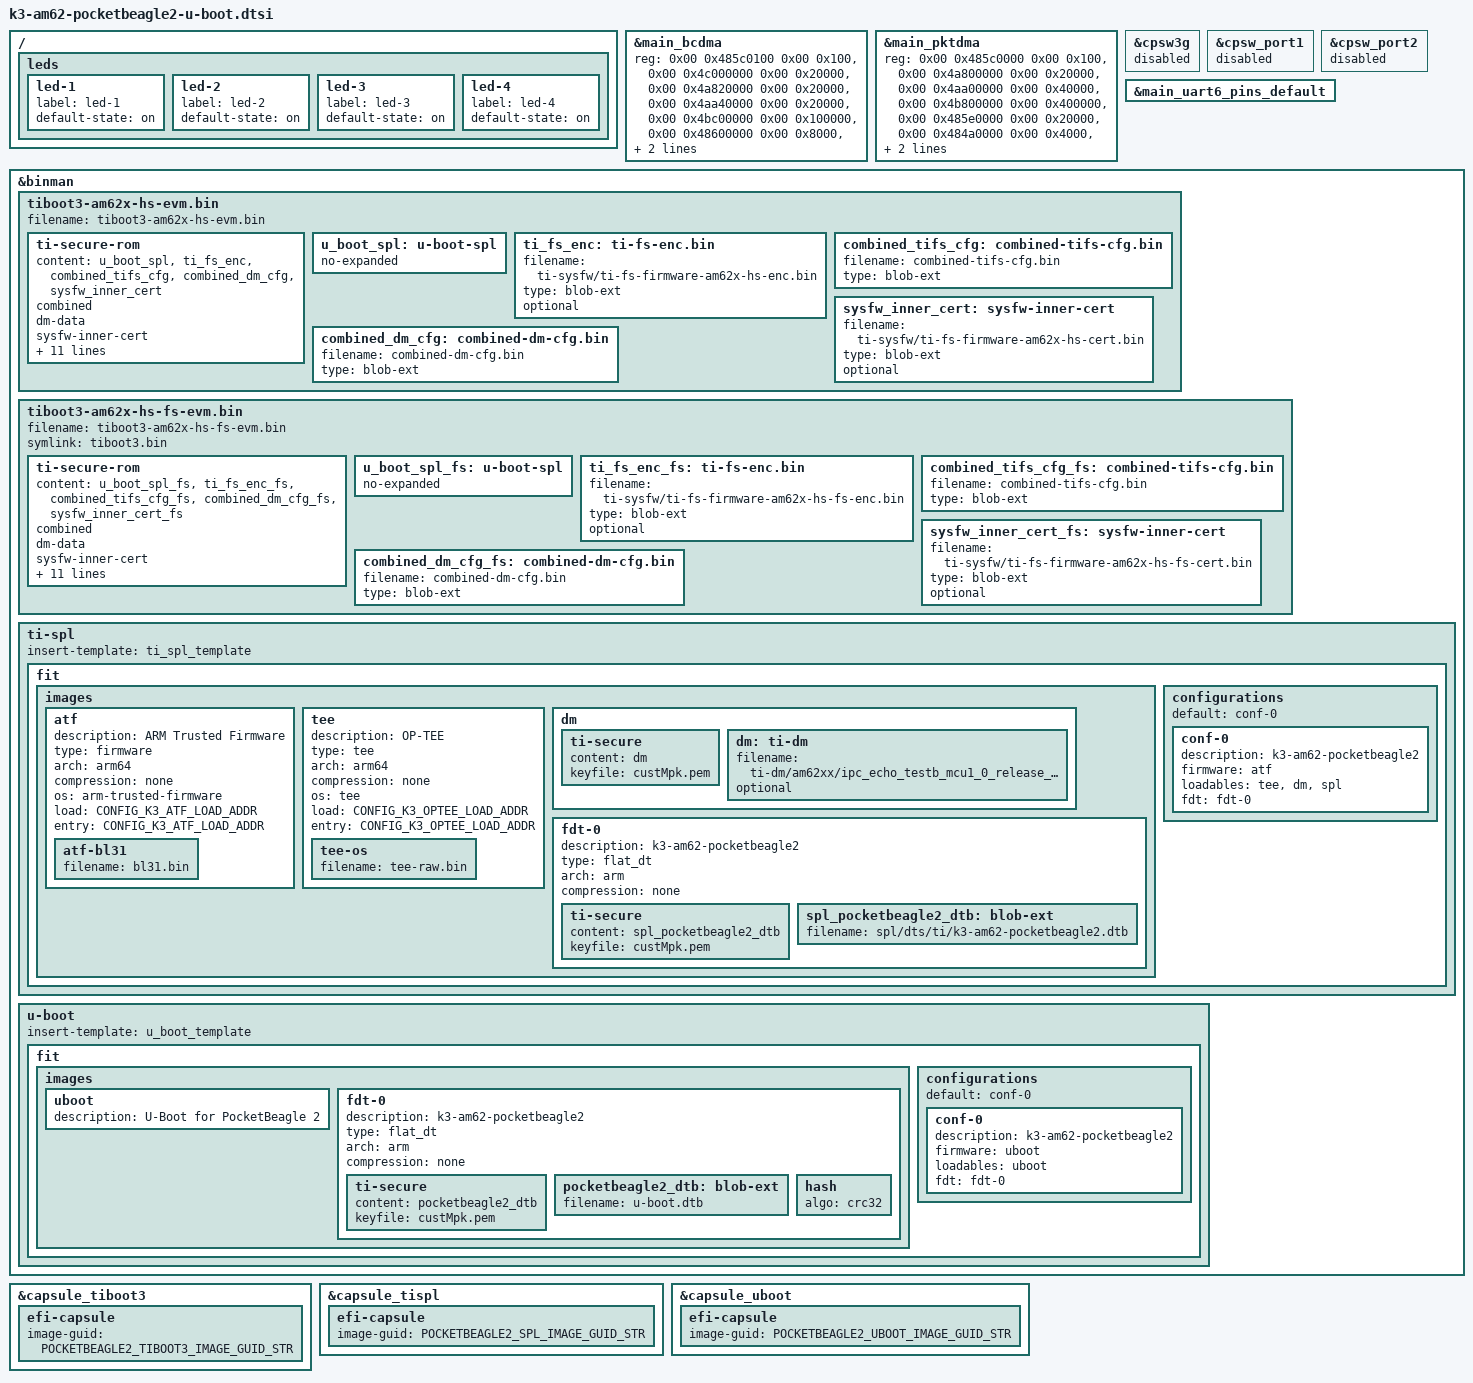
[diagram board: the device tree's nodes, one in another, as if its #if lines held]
// SPDX-License-Identifier: GPL-2.0
/*
 * AM625 PocketBeagle 2 dts file for SPLs
 * https://www.beagleboard.org/boards/pocketbeagle-2
 *
 * Copyright (C) 2024-2025 Texas Instruments Incorporated - https://www.ti.com/
 * Copyright (C) 2024-2025 Robert Nelson, BeagleBoard.org Foundation
 */

#include "k3-binman.dtsi"

/ {
	/* Keep the LEDs on by default to indicate life */
	leds {
		led-1 {
			label = "led-1";
			default-state = "on";
		};

		led-2 {
			label = "led-2";
			default-state = "on";
		};

		led-3 {
			label = "led-3";
			default-state = "on";
		};

		led-4 {
			label = "led-4";
			default-state = "on";
		};
	};
};

&main_bcdma {
	reg = <0x00 0x485c0100 0x00 0x100>,
	      <0x00 0x4c000000 0x00 0x20000>,
	      <0x00 0x4a820000 0x00 0x20000>,
	      <0x00 0x4aa40000 0x00 0x20000>,
	      <0x00 0x4bc00000 0x00 0x100000>,
	      <0x00 0x48600000 0x00 0x8000>,
	      <0x00 0x484a4000 0x00 0x2000>,
	      <0x00 0x484c2000 0x00 0x2000>;
	reg-names = "gcfg", "bchanrt", "rchanrt", "tchanrt", "ringrt",
		    "cfg", "tchan", "rchan";
	bootph-all;
};

&main_pktdma {
	reg = <0x00 0x485c0000 0x00 0x100>,
	      <0x00 0x4a800000 0x00 0x20000>,
	      <0x00 0x4aa00000 0x00 0x40000>,
	      <0x00 0x4b800000 0x00 0x400000>,
	      <0x00 0x485e0000 0x00 0x20000>,
	      <0x00 0x484a0000 0x00 0x4000>,
	      <0x00 0x484c0000 0x00 0x2000>,
	      <0x00 0x48430000 0x00 0x4000>;
	reg-names = "gcfg", "rchanrt", "tchanrt", "ringrt", "cfg",
		    "tchan", "rchan", "rflow";
	bootph-all;
};

&cpsw3g {
	status = "disabled";
};

&cpsw_port1 {
	status = "disabled";
};

&cpsw_port2 {
	status = "disabled";
};

&main_uart6_pins_default {
	bootph-all;
};

#if IS_ENABLED(CONFIG_TARGET_AM62X_R5_POCKETBEAGLE2)

&binman {
	tiboot3-am62x-hs-evm.bin {
		filename = "tiboot3-am62x-hs-evm.bin";
		ti-secure-rom {
			content = <&u_boot_spl>, <&ti_fs_enc>, <&combined_tifs_cfg>,
				  <&combined_dm_cfg>, <&sysfw_inner_cert>;
			combined;
			dm-data;
			sysfw-inner-cert;
			keyfile = "custMpk.pem";
			sw-rev = <1>;
			content-sbl = <&u_boot_spl>;
			content-sysfw = <&ti_fs_enc>;
			content-sysfw-data = <&combined_tifs_cfg>;
			content-sysfw-inner-cert = <&sysfw_inner_cert>;
			content-dm-data = <&combined_dm_cfg>;
			load = <CONFIG_SPL_TEXT_BASE>;
			load-sysfw = <0x40000>;
			load-sysfw-data = <0x67000>;
			load-dm-data = <0x43c3a800>;
		};

		u_boot_spl: u-boot-spl {
			no-expanded;
		};

		ti_fs_enc: ti-fs-enc.bin {
			filename = "ti-sysfw/ti-fs-firmware-am62x-hs-enc.bin";
			type = "blob-ext";
			optional;
		};

		combined_tifs_cfg: combined-tifs-cfg.bin {
			filename = "combined-tifs-cfg.bin";
			type = "blob-ext";
		};

		sysfw_inner_cert: sysfw-inner-cert {
			filename = "ti-sysfw/ti-fs-firmware-am62x-hs-cert.bin";
			type = "blob-ext";
			optional;
		};

		combined_dm_cfg: combined-dm-cfg.bin {
			filename = "combined-dm-cfg.bin";
			type = "blob-ext";
		};
	};
};

&binman {
	tiboot3-am62x-hs-fs-evm.bin {
		filename = "tiboot3-am62x-hs-fs-evm.bin";
		symlink = "tiboot3.bin";

		ti-secure-rom {
			content = <&u_boot_spl_fs>, <&ti_fs_enc_fs>, <&combined_tifs_cfg_fs>,
				  <&combined_dm_cfg_fs>, <&sysfw_inner_cert_fs>;
			combined;
			dm-data;
			sysfw-inner-cert;
			keyfile = "custMpk.pem";
			sw-rev = <1>;
			content-sbl = <&u_boot_spl_fs>;
			content-sysfw = <&ti_fs_enc_fs>;
			content-sysfw-data = <&combined_tifs_cfg_fs>;
			content-sysfw-inner-cert = <&sysfw_inner_cert_fs>;
			content-dm-data = <&combined_dm_cfg_fs>;
			load = <CONFIG_SPL_TEXT_BASE>;
			load-sysfw = <0x40000>;
			load-sysfw-data = <0x67000>;
			load-dm-data = <0x43c3a800>;
		};

		u_boot_spl_fs: u-boot-spl {
			no-expanded;
		};

		ti_fs_enc_fs: ti-fs-enc.bin {
			filename = "ti-sysfw/ti-fs-firmware-am62x-hs-fs-enc.bin";
			type = "blob-ext";
			optional;
		};

		combined_tifs_cfg_fs: combined-tifs-cfg.bin {
			filename = "combined-tifs-cfg.bin";
			type = "blob-ext";
		};

		sysfw_inner_cert_fs: sysfw-inner-cert {
			filename = "ti-sysfw/ti-fs-firmware-am62x-hs-fs-cert.bin";
			type = "blob-ext";
			optional;
		};

		combined_dm_cfg_fs: combined-dm-cfg.bin {
			filename = "combined-dm-cfg.bin";
			type = "blob-ext";
		};
	};
};

#include "k3-binman-capsule-r5.dtsi"

// Capsule update GUIDs in string form. See pocketbeagle2.h
#define POCKETBEAGLE2_TIBOOT3_IMAGE_GUID_STR "F0D53723-106E-5346-8A41-85EB2D07C720"

&capsule_tiboot3 {
	efi-capsule {
		image-guid = POCKETBEAGLE2_TIBOOT3_IMAGE_GUID_STR;
	};
};
#endif /* CONFIG_TARGET_AM62X_R5_POCKETBEAGLE2 */

#if IS_ENABLED(CONFIG_TARGET_AM62X_A53_POCKETBEAGLE2)

&binman {
	ti-spl {
		insert-template = <&ti_spl_template>;

		fit {
			images {
				atf {
					description = "ARM Trusted Firmware";
					type = "firmware";
					arch = "arm64";
					compression = "none";
					os = "arm-trusted-firmware";
					load = <CONFIG_K3_ATF_LOAD_ADDR>;
					entry = <CONFIG_K3_ATF_LOAD_ADDR>;
					atf-bl31 {
						filename = "bl31.bin";
					};
				};

				tee {
					description = "OP-TEE";
					type = "tee";
					arch = "arm64";
					compression = "none";
					os = "tee";
					load = <CONFIG_K3_OPTEE_LOAD_ADDR>;
					entry = <CONFIG_K3_OPTEE_LOAD_ADDR>;
					tee-os {
						filename = "tee-raw.bin";
					};
				};

				dm {
					ti-secure {
						content = <&dm>;
						keyfile = "custMpk.pem";
					};

					dm: ti-dm {
						filename = "ti-dm/am62xx/ipc_echo_testb_mcu1_0_release_strip.xer5f";
						optional;
					};
				};

				fdt-0 {
					description = "k3-am62-pocketbeagle2";
					type = "flat_dt";
					arch = "arm";
					compression = "none";

					ti-secure {
						content = <&spl_pocketbeagle2_dtb>;
						keyfile = "custMpk.pem";
					};

					spl_pocketbeagle2_dtb: blob-ext {
						filename = "spl/dts/ti/k3-am62-pocketbeagle2.dtb";
					};
				};
			};

			configurations {
				default = "conf-0";

				conf-0 {
					description = "k3-am62-pocketbeagle2";
					firmware = "atf";
					loadables = "tee", "dm", "spl";
					fdt = "fdt-0";
				};
			};
		};
	};
};

&binman {
	u-boot {
		insert-template = <&u_boot_template>;

		fit {
			images {
				uboot {
					description = "U-Boot for PocketBeagle 2";
				};

				fdt-0 {
					description = "k3-am62-pocketbeagle2";
					type = "flat_dt";
					arch = "arm";
					compression = "none";

					ti-secure {
						content = <&pocketbeagle2_dtb>;
						keyfile = "custMpk.pem";
					};

					pocketbeagle2_dtb: blob-ext {
						filename = "u-boot.dtb";
					};

					hash {
						algo = "crc32";
					};
				};
			};

			configurations {
				default = "conf-0";

				conf-0 {
					description = "k3-am62-pocketbeagle2";
					firmware = "uboot";
					loadables = "uboot";
					fdt = "fdt-0";
				};
			};
		};
	};
};

#include "k3-binman-capsule.dtsi"

// Capsule update GUIDs in string form. See pocketbeagle2.h
#define POCKETBEAGLE2_SPL_IMAGE_GUID_STR "C73FDEA2-3964-58C8-8A25-E55102172E1D"
#define POCKETBEAGLE2_UBOOT_IMAGE_GUID_STR "520E1012-DE6C-5992-B43A-95D53D8332F2"

&capsule_tispl {
	efi-capsule {
		image-guid = POCKETBEAGLE2_SPL_IMAGE_GUID_STR;
	};
};

&capsule_uboot {
	efi-capsule {
		image-guid = POCKETBEAGLE2_UBOOT_IMAGE_GUID_STR;
	};
};
#endif /* CONFIG_TARGET_AM62X_A53_POCKETBEAGLE2 */
